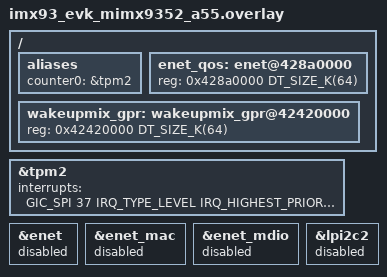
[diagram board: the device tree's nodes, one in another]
/*
 * Copyright 2023-2025 NXP
 *
 * SPDX-License-Identifier: BSD-3-Clause
 */

#define IRQ_HIGHEST_PRIORITY	0

/ {
	aliases {
		counter0 = &tpm2;
	};

	enet_qos: enet@428a0000 {
		reg = <0x428a0000 DT_SIZE_K(64)>;
	};

	wakeupmix_gpr: wakeupmix_gpr@42420000 {
		reg = <0x42420000 DT_SIZE_K(64)>;
	};
};

&tpm2 {
	interrupts = <GIC_SPI 37 IRQ_TYPE_LEVEL
		IRQ_HIGHEST_PRIORITY>;
	status = "okay";
};

&enet {
	status = "disabled";
};

&enet_mac {
	status = "disabled";
};

&enet_mdio {
	status = "disabled";
};

&lpi2c2 {
	status = "disabled";
};
